# PIC32CX5109BZ36048_SL3 register map
Vendor: Microchip Technology; Series: PIC32CXBZ36; File version: 0
CPU: CM4 r0p1, little endian, MPU, FPU, 3 interrupt priority bits, 43 interrupts
Registers are 32-bit, read-write, reset 0x0 unless marked. A register's access mark holds for its fields unless they carry their own. Offsets are from the block's base; [hi:lo] are bit positions; {n}, {i} and the like mark numbered series; 'fields as' and 'values as' point back to an identical list.

## CFG
Base 0x44000000
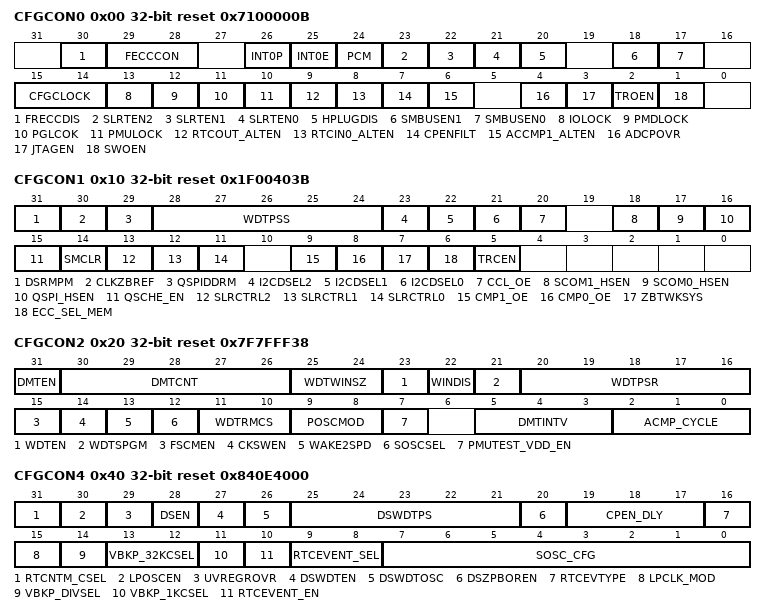
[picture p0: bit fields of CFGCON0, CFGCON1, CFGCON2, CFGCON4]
0x00 CFGCON0 reset 0x7100000B
  [30] FRECCDIS — Flex RAM ECC Control
  [29:28] FECCCON — Flash ECC Control
  [26] INT0P — INT0P Polarity
  [25] INT0E — INT0 Enable
  [24] PCM — PCHE I/D Cacheable Mode
  [23] SLRTEN2 — SLRT Enable for SERCOM2
  [22] SLRTEN1 — SLRT Enable for SERCOM1
  [21] SLRTEN0 — SLRT Enable for SERCOM0
  [20] HPLUGDIS — Hot Plugging Disable
  [18] SMBUSEN1 — SMBus Enable for SERCOM1
  [17] SMBUSEN0 — SMBus Enable for SERCOM0
  [15:14] CFGCLOCK — Configuration Register Lock
  [13] IOLOCK
  [12] PMDLOCK — Peripheral Module Disable (PMD) LOCK
  [11] PGLCOK — Permission Group LOCK
  [10] PMULOCK — PMU Controller Register LOCK
  [9] RTCOUT_ALTEN — RTCOUT Alternate Enable
  [8] RTCIN0_ALTEN — RTCIN0 Alternate Enable
  [7] CPENFILT — ADC CP Filter Enable
  [6] ACCMP1_ALTEN — AC CMP1 Alternate Enable
  [4] ADCPOVR — ADC Charge Pump Override
  [3] JTAGEN — JTAG Enable
  [2] TROEN — Trace Output Enable
  [1] SWOEN — SWO enable on 2-wire debug interface
{0x4+0x10*i} CFGCON{i}CLR (i=0..2) — Bit clear register
{0x8+0x10*i} CFGCON{i}SET (i=0..2) — Bit set register
{0xC+0x10*i} CFGCON{i}INV (i=0..2) — Bit invert register
0x10 CFGCON1 reset 0x1F00403B
  [31] DSRMPM — Deep Sleep Retention Memory Power Mode
  [30] CLKZBREF — External Reference Clock ZB Enable
  [29] QSPIDDRM — QSPI DDR Mode Clock Enable
  [28:24] WDTPSS — Watchdog Timer Post-scale Select Sleep
  [23] I2CDSEL2 — I2C Delay Select for SERCOM2
  [22] I2CDSEL1 — I2C Delay Select for SERCOM1
  [21] I2CDSEL0 — I2C Delay Select for SERCOM0
  [20] CCL_OE — CCL Pads (via PPS) Output Enable
  [18] SCOM1_HSEN — SERCOM1 (Direct)High Speed Pin Enable
  [17] SCOM0_HSEN — SERCOM0 (Direct)High Speed Pin Enable
  [16] QSPI_HSEN — QSPI (Direct) Enable
  [15] QSCHE_EN — QSPI Address Space Cache Attribute
  [14] SMCLR — Selects CRU handling of MCLR Control
  [13] SLRCTRL2 — I2C Slew Rate Control for SERCOM2
  [12] SLRCTRL1 — I2C Slew Rate Control for SERCOM1
  [11] SLRCTRL0 — I2C Slew Rate Control for SERCOM0
  [9] CMP1_OE — Analog Comparator-1 Output Enable
  [8] CMP0_OE — Analog Comparator-0 Output Enable
  [7] ZBTWKSYS — ZBT Subsystem External Wake-up source
  [6] ECC_SEL_MEM — ECC row selection bit
  [5] TRCEN — Trace Enable
0x20 CFGCON2 reset 0x7F7FFF38
  [31] DMTEN — Dead Man Timer Enable
  [30:26] DMTCNT — Dead Man Timer Count Select
  [25:24] WDTWINSZ — Watchdog Timer Window Size
  [23] WDTEN — Watchdog Timer Enable
  [22] WINDIS — Windowed Watchdog Timer Disable
  [21] WDTSPGM — Watchdog Timer Stop during Flash Programming
  [20:16] WDTPSR — Watchdog Timer Post-scale Select Run
  [15] FSCMEN — Fail-Safe Clock Monitor Enable
  [14] CKSWEN — Software Clock Switching Enable
  [13] WAKE2SPD — 2-Speed startup enabled in Sleep mode
  [12] SOSCSEL — SOSC Selection Configuration
  [11:10] WDTRMCS — WDT RUN Mode Clock Select
  [9:8] POSCMOD — Primary Oscillator Configuration
  [7] PMUTEST_VDD_EN — PMU Test Output or VDD/2 Enable via ADC IE12
  [5:3] DMTINTV — Dead Man Timer Count Window Interval
  [2:0] ACMP_CYCLE — AC SIB Comparator Result Wait Cycles
0x40 CFGCON4 reset 0x840E4000
  [31] RTCNTM_CSEL — RTC Counter Mode Clock Select
  [30] LPOSCEN — Low Power (Secondary) Oscillator Enable
  [29] UVREGROVR — ULPVREG Retention Mode Override
  [28] DSEN — Deep Sleep Bit Enable
  [27] DSWDTEN — Deep Sleep Watchdog Timer Enable
  [26] DSWDTOSC — Deep Sleep Watchdog Timer Reference Clock Select
  [25:21] DSWDTPS — Deep Sleep Watchdog Timer Postscale Select
  [20] DSZPBOREN — Deep Sleep Zero-Power BOR Enable
  [19:17] CPEN_DLY — Charge-pump ready digital delay
  [16] RTCEVTYPE — RTC Event Type
  [15] LPCLK_MOD — LPCLK modifier in counter/delay mode
  [14] VBKP_DIVSEL — VDDBUKPCORE LPCLK Clock Divider Selection
  [13:12] VBKP_32KCSEL — VDDBUKPCORE 32KHz clock source selection
  [11] VBKP_1KCSEL — VDDBUKPCORE LPCLK Clock Selection
  [10] RTCEVENT_EN — Pad Output Enable for MCHP legacy RTC event output
  [9:8] RTCEVENT_SEL — RTC Event Selection
  [7:0] SOSC_CFG — SOSC Configuration
0x44 CFGCON4CLR — Bit clear register
0x48 CFGCON4SET — Bit set register
0x4C CFGCON4INV — Bit invert register
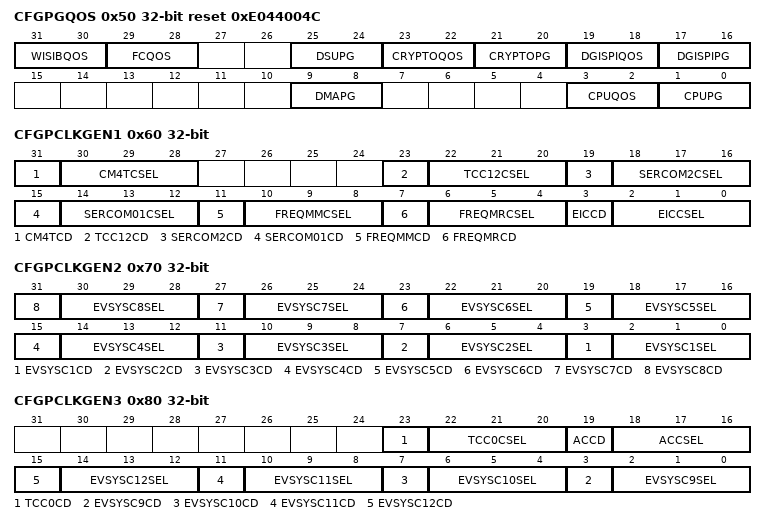
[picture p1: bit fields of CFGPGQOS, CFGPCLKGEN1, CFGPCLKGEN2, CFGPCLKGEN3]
0x50 CFGPGQOS reset 0xE044004C
  [31:30] WISIBQOS — Wireless SIB QOS Control
  [29:28] FCQOS — FC Controller QOS Control
  [25:24] DSUPG — DSU Permission Group
  [23:22] CRYPTOQOS — Crypto QOS Control
  [21:20] CRYPTOPG — Crypto Permission Group
  [19:18] DGISPIQOS — ADC Controller QOS Control
  [17:16] DGISPIPG — ADC Controller Permission Group
  [9:8] DMAPG — DMA (Rd/Wr) Permission Group
  [3:2] CPUQOS — CPU I/D and System Bus QOS Control
  [1:0] CPUPG — CPU (Code) Permission Group
0x54 CFGPGQOSCLR — Bit clear register
0x58 CFGPGQOSSET — Bit set register
0x5C CFGPGQOSINV — Bit invert register
0x60 CFGPCLKGEN1
  [31] CM4TCD — CM4T Clock Disable
    1=ON (Enable PGCLK); 0=OFF (Disable PGCLK)
  [30:28] CM4TCSEL — CM4T Clock Selection
    0=NO_CLK (No Clock); {v}=REFO{v} (Reference Clock {v}) (v=1..6); 7=LPCLK (32 KHz Low Power Clock)
  [23] TCC12CD — TCC1/2 Clock Disable
    1=ON (Enable PGCLK); 0=OFF (Disable PGCLK)
  [22:20] TCC12CSEL — TCC1/2 Clock Selection
    values as CM4TCSEL
  [19] SERCOM2CD — SERCOM2/3 Clock Disable
    1=ON (Enable PGCLK); 0=OFF (Disable PGCLK)
  [18:16] SERCOM2CSEL — SERCOM2/3 Clock Selection
    values as CM4TCSEL
  [15] SERCOM01CD — SERCOM0/1 Clock Disable
    1=ON (Enable PGCLK); 0=OFF (Disable PGCLK)
  [14:12] SERCOM01CSEL — SERCOM0/1 Clock Selection
    values as CM4TCSEL
  [11] FREQMMCD — FREQMMC Clock Disable
    1=ON (Enable PGCLK); 0=OFF (Disable PGCLK)
  [10:8] FREQMMCSEL — FREQMMC Clock Selection
    values as CM4TCSEL
  [7] FREQMRCD — FREQMRC Clock Disable
    1=ON (Enable PGCLK); 0=OFF (Disable PGCLK)
  [6:4] FREQMRCSEL — FREQMRC Clock Selection
    values as CM4TCSEL
  [3] EICCD — EIC Clock Disable
    1=ON (Enable PGCLK); 0=OFF (Disable PGCLK)
  [2:0] EICCSEL — EIC Clock Selection
    values as CM4TCSEL
{0x54+0x10*i} CFGPCLKGEN{i}CLR (i=1..4) — Bit clear register
{0x58+0x10*i} CFGPCLKGEN{i}SET (i=1..4) — Bit set register
{0x5C+0x10*i} CFGPCLKGEN{i}INV (i=1..4) — Bit invert register
0x70 CFGPCLKGEN2
  [4n-1] EVSYSC{n}CD (n=1..8) — EVSYSC{n} Clock Disable
    1=ON (Enable PGCLK); 0=OFF (Disable PGCLK)
  [4n-2:4n-4] EVSYSC{n}SEL (n=1..8) — EVSYSC{n} Peripheral Clock Selection
    values as CFGPCLKGEN1.CM4TCSEL
0x80 CFGPCLKGEN3
  [23] TCC0CD — TCC0 Clock Disable
    1=ON (Enable PGCLK); 0=OFF (Disable PGCLK)
  [22:20] TCC0CSEL — TCC0 Peripheral Clock Selection
    values as CFGPCLKGEN1.CM4TCSEL
  [19] ACCD — AC Clock Disable
    1=ON (Enable PGCLK); 0=OFF (Disable PGCLK)
  [18:16] ACCSEL — AC Peripheral Clock Selection
    values as CFGPCLKGEN1.CM4TCSEL
  [4n-33] EVSYSC{n}CD (n=9..12) — EVSYSC{n} Clock Disable
    1=ON (Enable PGCLK); 0=OFF (Disable PGCLK)
  [4n-34:4n-36] EVSYSC{n}SEL (n=9..12) — EVSYSC{n} Peripheral Clock Selection
    values as CFGPCLKGEN1.CM4TCSEL
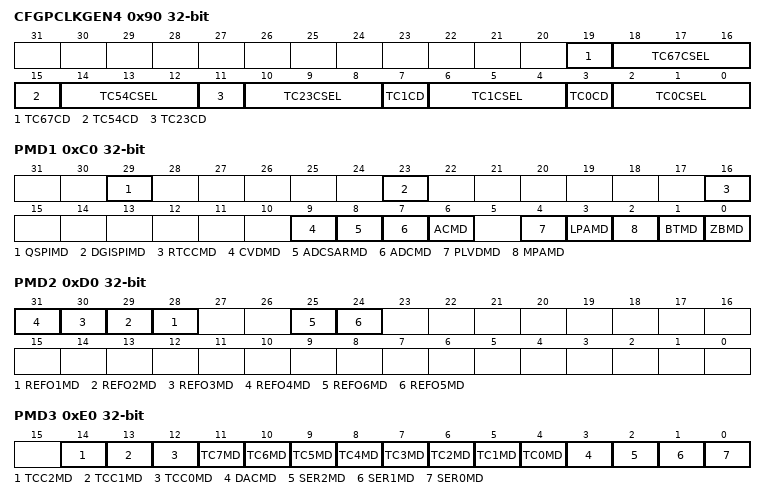
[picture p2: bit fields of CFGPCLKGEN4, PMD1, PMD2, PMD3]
0x90 CFGPCLKGEN4
  [19] TC67CD — TC67CD Clock Disable
    1=ON (Enable PGCLK); 0=OFF (Disable PGCLK)
  [18:16] TC67CSEL — TC67CSEL Peripheral Clock Selection
    values as CFGPCLKGEN1.CM4TCSEL
  [15] TC54CD — TC54CD Clock Disable
    1=ON (Enable PGCLK); 0=OFF (Disable PGCLK)
  [14:12] TC54CSEL — TC54CSEL Peripheral Clock Selection
    values as CFGPCLKGEN1.CM4TCSEL
  [11] TC23CD — TC23CD Clock Disable
    1=ON (Enable PGCLK); 0=OFF (Disable PGCLK)
  [10:8] TC23CSEL — TC23CSEL Peripheral Clock Selection
    values as CFGPCLKGEN1.CM4TCSEL
  [7] TC1CD — TC1 Clock Disable
    1=ON (Enable PGCLK); 0=OFF (Disable PGCLK)
  [6:4] TC1CSEL — TC1 Peripheral Clock Selection
    values as CFGPCLKGEN1.CM4TCSEL
  [3] TC0CD — TC0 Clock Disable
    1=ON (Enable PGCLK); 0=OFF (Disable PGCLK)
  [2:0] TC0CSEL — TC0 Peripheral Clock Selection
    values as CFGPCLKGEN1.CM4TCSEL
0xA0 USER_ID
  [15:0] USER_ID — User unique ID, readable using the SWD USER_ID instruction
0xA4 USER_IDCLR — Bit clear register
0xA8 USER_IDSET — Bit set register
0xAC USER_IDINV — Bit invert register
0xB0 SYSKEY
  [31:0] SYSKEY — System Key
0xC0 PMD1
  [29] QSPIMD — SQI Module Disable
  [23] DGISPIMD — DGI SPI Module Disable
  [16] RTCCMD — RTCC Module Disable
  [9] CVDMD — Shared ADC SAR Core Module Disable
  [8] ADCSARMD — Shared ADC SAR Core Module Disable
  [7] ADCMD — ADC Controller Module Disable
  [6] ACMD — AC Module Disable
  [4] PLVDMD — PLVD Module Disable
  [3] LPAMD — RF LPA Module Disable
  [2] MPAMD — RF MPA Module Disable
  [1] BTMD — Bluetooth Module Disable
  [0] ZBMD — ZigBee Module Disable
{0xB4+0x10*i} PMD{i}CLR (i=1..3) — Bit clear register
{0xB8+0x10*i} PMD{i}SET (i=1..3) — Bit set register
{0xBC+0x10*i} PMD{i}INV (i=1..3) — Bit invert register
0xD0 PMD2
  [n+27] REFO{n}MD (n=1..4) — Reference (Clock) Out {n} Module Disable
  [25] REFO6MD — Reference (Clock) Out 6 Module Disable
  [24] REFO5MD — Reference (Clock) Out 5 Module Disable
0xE0 PMD3
  [14] TCC2MD — TCC2 Module Disable
  [13] TCC1MD — TCC1 Module Disable
  [12] TCC0MD — TCC0 Module Disable
  [n+4] TC{n}MD (n=0..7) — TC{n} Module Disable
  [3] DACMD — DAC Module Disable
  [2] SER2MD — SERCOM2 Module Disable
  [1] SER1MD — SERCOM1 Module Disable
  [0] SER0MD — SERCOM0 Module Disable
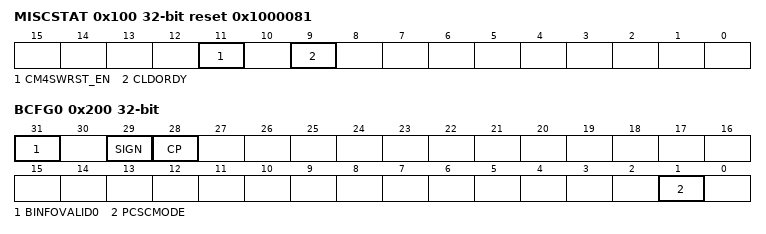
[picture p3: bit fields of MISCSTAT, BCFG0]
0x100 MISCSTAT reset 0x1000081
  [11] CM4SWRST_EN — CM4 SW Reset Enable
  [9] CLDORDY — CLDO Ready
0x140 ID ro — Device ID
0x200 BCFG0 ro
  [31] BINFOVALID0 — First 256-bit BCFG information Valid
  [29] SIGN — Flash SIGN
  [28] CP — Boot Code Protect
  [1] PCSCMODE — PCHE Single cache Mode
